# ATSAMG55J19 register map
Vendor: Microchip Technology; Series: SAMG55; File version: 0
CPU: CM4 r0p1, little endian, MPU, FPU, 4 interrupt priority bits, 50 interrupts
Registers are 32-bit, read-write, reset 0x0 unless marked. A register's access mark holds for its fields unless they carry their own. Offsets are from the block's base; [hi:lo] are bit positions; {n}, {i} and the like mark numbered series.

## USART0 — Universal Synchronous Asynchronous Receiver Transmitter
Base 0x4000C200; register names take the prefix USART_
Same registers: USART5 0x40008200, USART3 0x40018200, USART4 0x4001C200, USART1 0x40020200, USART2 0x40024200, USART7 0x40034200, USART6 0x40040200
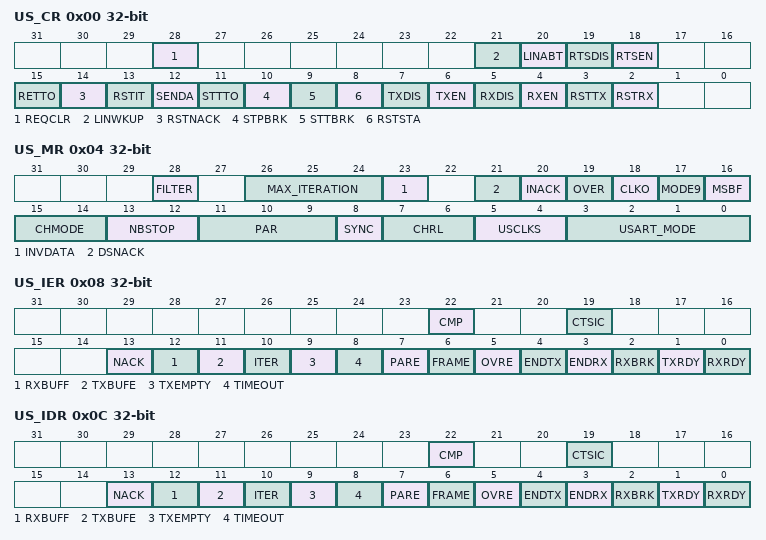
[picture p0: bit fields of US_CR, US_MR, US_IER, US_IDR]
0x00 US_CR wo — Control Register
  [28] REQCLR — Request to Clear the Comparison Trigger
  [21] LINWKUP — Send LIN Wakeup Signal
  [20] LINABT — Abort LIN Transmission
  [19] RTSDIS — Request to Send Disable
  [18] RTSEN — Request to Send Enable
  [15] RETTO — Start Time-out Immediately
  [14] RSTNACK — Reset Non Acknowledge
  [13] RSTIT — Reset Iterations
  [12] SENDA — Send Address
  [11] STTTO — Clear TIMEOUT Flag and Start Time-out After Next Character Received
  [10] STPBRK — Stop Break
  [9] STTBRK — Start Break
  [8] RSTSTA — Reset Status Bits
  [7] TXDIS — Transmitter Disable
  [6] TXEN — Transmitter Enable
  [5] RXDIS — Receiver Disable
  [4] RXEN — Receiver Enable
  [3] RSTTX — Reset Transmitter
  [2] RSTRX — Reset Receiver
0x04 US_MR — Mode Register
  [28] FILTER — Receive Line Filter
  [26:24] MAX_ITERATION — Maximum Number of Automatic Iteration
  [23] INVDATA — Inverted Data
  [21] DSNACK — Disable Successive NACK
  [20] INACK — Inhibit Non Acknowledge
  [19] OVER — Oversampling Mode
  [18] CLKO — Clock Output Select
  [17] MODE9 — 9-bit Character Length
  [16] MSBF — Bit Order
  [15:14] CHMODE — Channel Mode
    0=NORMAL (Normal mode); 1=AUTOMATIC (Automatic Echo. Receiver input is connected to the TXD pin.); 2=LOCAL_LOOPBACK (Local Loopback. Transmitter output is connected to the Receiver Input.); 3=REMOTE_LOOPBACK (Remote Loopback. RXD pin is internally connected to the TXD pin.)
  [13:12] NBSTOP — Number of Stop Bits
    0=_1_BIT (1 stop bit); 1=_1_5_BIT (1.5 stop bits (SYNC = 0) or reserved (SYNC = 1)); 2=_2_BIT (2 stop bits)
  [11:9] PAR — Parity Type
    0=EVEN (Even parity); 1=ODD (Odd parity); 2=SPACE (Parity forced to 0 (Space)); 3=MARK (Parity forced to 1 (Mark)); 4=NO (No parity); 6=MULTIDROP (Multidrop mode)
  [8] SYNC — Synchronous Mode Select
  [7:6] CHRL — Character Length
    {v}=_{v+5}_BIT (Character length is {v+5} bits) (v=0..3)
  [5:4] USCLKS — Clock Selection
    0=MCK (Peripheral clock is selected); 1=DIV (Peripheral clock divided (DIV=8) is selected); 2=PMC_PCK (PMC programmable clock (PCK) is selected.If the SCK pin is driven (CLKO=1), the CD field must be greater than 1.); 3=SCK (External pin (SCK) is selected)
  [3:0] USART_MODE — USART Mode of Operation
    0=NORMAL (Normal mode); 1=RS485 (RS485 mode); 2=HW_HANDSHAKING (Hardware Handshaking); 4=IS07816_T_0 (IS07816 Protocol: T = 0); 6=IS07816_T_1 (IS07816 Protocol: T = 1); 8=IRDA (IrDA mode); 10=LIN_MASTER (LIN master mode); 11=LIN_SLAVE (LIN Slave mode); 14=SPI_MASTER (SPI master mode); 15=SPI_SLAVE (SPI Slave mode)
0x08 US_IER wo — Interrupt Enable Register
  [22] CMP — Comparison Interrupt Enable
  [19] CTSIC — Clear to Send Input Change Interrupt Enable
  [13] NACK — Non Acknowledge Interrupt Enable
  [12] RXBUFF — Receive Buffer Full Interrupt Enable (available in all USART modes of operation)
  [11] TXBUFE — Transmit Buffer Empty Interrupt Enable (available in all USART modes of operation)
  [10] ITER — Max number of Repetitions Reached Interrupt Enable
  [9] TXEMPTY — TXEMPTY Interrupt Enable
  [8] TIMEOUT — Time-out Interrupt Enable
  [7] PARE — Parity Error Interrupt Enable
  [6] FRAME — Framing Error Interrupt Enable
  [5] OVRE — Overrun Error Interrupt Enable
  [4] ENDTX — End of Transmit Buffer Interrupt Enable (available in all USART modes of operation)
  [3] ENDRX — End of Receive Buffer Interrupt Enable (available in all USART modes of operation)
  [2] RXBRK — Receiver Break Interrupt Enable
  [1] TXRDY — TXRDY Interrupt Enable
  [0] RXRDY — RXRDY Interrupt Enable
0x0C US_IDR wo — Interrupt Disable Register
  [22] CMP — Comparison Interrupt Disable
  [19] CTSIC — Clear to Send Input Change Interrupt Disable
  [13] NACK — Non Acknowledge Interrupt Disable
  [12] RXBUFF — Receive Buffer Full Interrupt Enable (available in all USART modes of operation)
  [11] TXBUFE — Transmit Buffer Empty Interrupt Enable (available in all USART modes of operation)
  [10] ITER — Max Number of Repetitions Reached Interrupt Disable
  [9] TXEMPTY — TXEMPTY Interrupt Disable
  [8] TIMEOUT — Time-out Interrupt Disable
  [7] PARE — Parity Error Interrupt Disable
  [6] FRAME — Framing Error Interrupt Disable
  [5] OVRE — Overrun Error Interrupt Enable
  [4] ENDTX — End of Transmit Buffer Interrupt Disable (available in all USART modes of operation)
  [3] ENDRX — End of Receive Buffer Interrupt Enable (available in all USART modes of operation)
  [2] RXBRK — Receiver Break Interrupt Disable
  [1] TXRDY — TXRDY Interrupt Disable
  [0] RXRDY — RXRDY Interrupt Disable
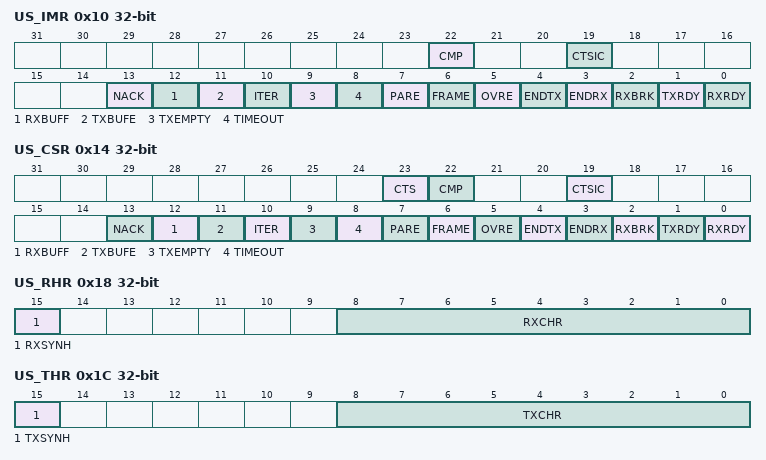
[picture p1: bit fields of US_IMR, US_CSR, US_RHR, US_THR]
0x10 US_IMR ro — Interrupt Mask Register
  [22] CMP — Comparison Interrupt Mask
  [19] CTSIC — Clear to Send Input Change Interrupt Mask
  [13] NACK — Non Acknowledge Interrupt Mask
  [12] RXBUFF — Receive Buffer Full Interrupt Mask (available in all USART modes of operation)
  [11] TXBUFE — Transmit Buffer Empty Interrupt Mask (available in all USART modes of operation)
  [10] ITER — Max Number of Repetitions Reached Interrupt Mask
  [9] TXEMPTY — TXEMPTY Interrupt Mask
  [8] TIMEOUT — Time-out Interrupt Mask
  [7] PARE — Parity Error Interrupt Mask
  [6] FRAME — Framing Error Interrupt Mask
  [5] OVRE — Overrun Error Interrupt Mask
  [4] ENDTX — End of Transmit Buffer Interrupt Mask (available in all USART modes of operation)
  [3] ENDRX — End of Receive Buffer Interrupt Mask (available in all USART modes of operation)
  [2] RXBRK — Receiver Break Interrupt Mask
  [1] TXRDY — TXRDY Interrupt Mask
  [0] RXRDY — RXRDY Interrupt Mask
0x14 US_CSR ro — Channel Status Register
  [23] CTS — Image of CTS Input
  [22] CMP — Comparison Status (cleared by writing a one to the bit US_CR.RSTSTA command)
  [19] CTSIC — Clear to Send Input Change Flag (cleared on read)
  [13] NACK — Non Acknowledge Interrupt (cleared by writing a one to the bit US_CR.RSTNACK)
  [12] RXBUFF — RX Buffer Full (cleared by writing US_RCR or US_RNCR)
  [11] TXBUFE — TX Buffer Empty (cleared by writing US_TCR or US_TNCR)
  [10] ITER — Max Number of Repetitions Reached (cleared by writing a one to the bit US_CR.RSTIT)
  [9] TXEMPTY — Transmitter Empty (cleared by writing US_THR)
  [8] TIMEOUT — Receiver Time-out (cleared by writing a one to the bit US_CR.STTTO)
  [7] PARE — Parity Error (cleared by writing a one to the US_CR.RSTSTA)
  [6] FRAME — Framing Error (cleared by writing a one to the bit US_CR.RSTSTA)
  [5] OVRE — Overrun Error (cleared by writing a one to the bit US_CR.RSTSTA)
  [4] ENDTX — End of TX Buffer (cleared by writing US_TCR or US_TNCR)
  [3] ENDRX — End of RX Buffer (cleared by writing US_RCR or US_RNCR)
  [2] RXBRK — Break Received/End of Break (cleared by writing a one to the bit US_CR.RSTSTA)
  [1] TXRDY — Transmitter Ready (cleared by writing US_THR)
  [0] RXRDY — Receiver Ready (cleared by reading US_RHR)
0x18 US_RHR ro — Receive Holding Register
  [15] RXSYNH — Received Sync
  [8:0] RXCHR — Received Character
0x1C US_THR wo — Transmit Holding Register
  [15] TXSYNH — Sync Field to be Transmitted
  [8:0] TXCHR — Character to be Transmitted
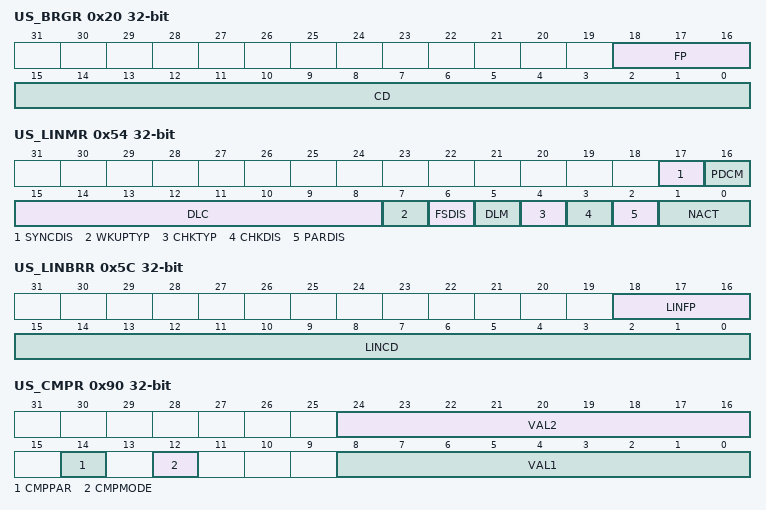
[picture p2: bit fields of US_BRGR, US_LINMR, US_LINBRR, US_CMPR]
0x20 US_BRGR — Baud Rate Generator Register
  [18:16] FP — Fractional Part
  [15:0] CD — Clock Divider
0x24 US_RTOR — Receiver Time-out Register
  [16:0] TO — Time-out Value
0x28 US_TTGR — Transmitter Timeguard Register
  [7:0] TG — Timeguard Value
0x40 US_FIDI — FI DI Ratio Register
  [15:0] FI_DI_RATIO — FI Over DI Ratio Value
0x44 US_NER ro — Number of Errors Register
  [7:0] NB_ERRORS — Number of Errors
0x4C US_IF — IrDA Filter Register
  [7:0] IRDA_FILTER
0x54 US_LINMR — LIN Mode Register
  [17] SYNCDIS — Synchronization Disable
  [16] PDCM — PDC Mode
  [15:8] DLC — Data Length Control
  [7] WKUPTYP — Wakeup Signal Type
  [6] FSDIS — Frame Slot Mode Disable
  [5] DLM — Data Length Mode
  [4] CHKTYP — Checksum Type
  [3] CHKDIS — Checksum Disable
  [2] PARDIS — Parity Disable
  [1:0] NACT — LIN Node Action
    0=PUBLISH (The USART transmits the response.); 1=SUBSCRIBE (The USART receives the response.); 2=IGNORE (The USART does not transmit and does not receive the response.)
0x58 US_LINIR — LIN Identifier Register
  [7:0] IDCHR — Identifier Character
0x5C US_LINBRR ro — LIN Baud Rate Register
  [18:16] LINFP — Fractional Part after Synchronization
  [15:0] LINCD — Clock Divider after Synchronization
0x90 US_CMPR — Comparison Register
  [24:16] VAL2 — Second Comparison Value for Received Character
  [14] CMPPAR — Compare Parity
  [12] CMPMODE — Comparison Mode
    0=FLAG_ONLY (Any character is received and comparison function drives CMP flag.); 1=START_CONDITION (Comparison condition must be met to start reception of all incoming charactersuntil REQCLR is set.)
  [8:0] VAL1 — First Comparison Value for Received Character
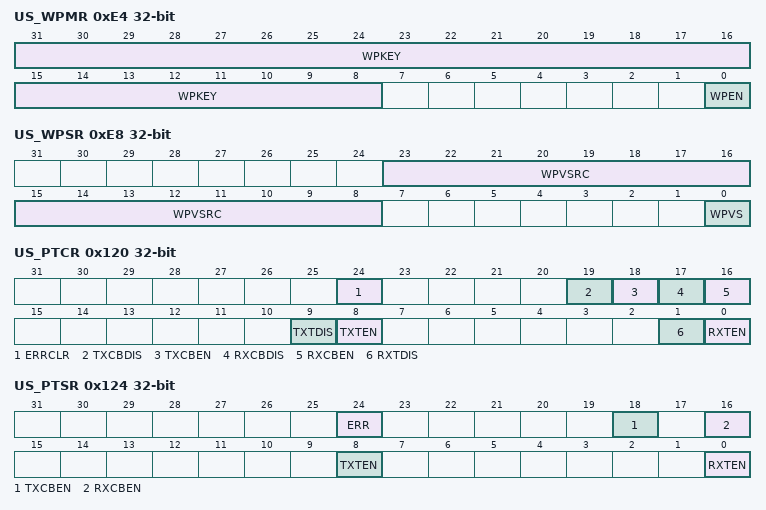
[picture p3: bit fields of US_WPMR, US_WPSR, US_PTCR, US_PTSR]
0xE4 US_WPMR — Write Protection Mode Register
  [31:8] WPKEY — Write Protection Key
    0x555341=PASSWD (Writing any other value in this field aborts the write operation of the WPEN bit. Always reads as 0.)
  [0] WPEN — Write Protection Enable
0xE8 US_WPSR ro — Write Protection Status Register
  [23:8] WPVSRC — Write Protection Violation Source
  [0] WPVS — Write Protection Violation Status
0x100 US_RPR — Receive Pointer Register
  [31:0] RXPTR
0x104 US_RCR — Receive Counter Register
  [15:0] RXCTR
0x108 US_TPR — Transmit Pointer Register
  [31:0] TXPTR — Transmit Counter Register
0x10C US_TCR — Transmit Counter Register
  [15:0] TXCTR
0x110 US_RNPR — Receive Next Pointer Register
  [31:0] RXNPTR — Receive Next Pointer
0x114 US_RNCR — Receive Next Counter Register
  [15:0] RXNCTR — Receive Next Counter
0x118 US_TNPR — Transmit Next Pointer Register
  [31:0] TXNPTR — Transmit Next Pointer
0x11C US_TNCR — Transmit Next Counter Register
  [15:0] TXNCTR — Transmit Counter Next
0x120 US_PTCR wo — Transfer Control Register
  [24] ERRCLR — Transfer Bus Error Clear
  [19] TXCBDIS — Transmitter Circular Buffer Disable
  [18] TXCBEN — Transmitter Circular Buffer Enable
  [17] RXCBDIS — Receiver Circular Buffer Disable
  [16] RXCBEN — Receiver Circular Buffer Enable
  [9] TXTDIS — Transmitter Transfer Disable
  [8] TXTEN — Transmitter Transfer Enable
  [1] RXTDIS — Receiver Transfer Disable
  [0] RXTEN — Receiver Transfer Enable
0x124 US_PTSR ro — Transfer Status Register
  [24] ERR — Transfer Bus Error
  [18] TXCBEN — Transmitter Circular Buffer Enable
  [16] RXCBEN — Receiver Circular Buffer Enable
  [8] TXTEN — Transmitter Transfer Enable
  [0] RXTEN — Receiver Transfer Enable
